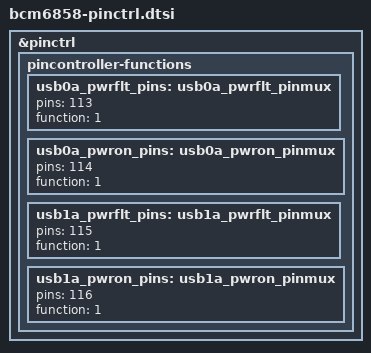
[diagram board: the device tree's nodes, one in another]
&pinctrl {
	pincontroller-functions {
		usb0a_pwrflt_pins: usb0a_pwrflt_pinmux {
			pins = <113>;
			function = <1>;
		};

		usb0a_pwron_pins: usb0a_pwron_pinmux {
			pins = <114>;
			function = <1>;
		};

		usb1a_pwrflt_pins: usb1a_pwrflt_pinmux {
			pins = <115>;
			function = <1>;
		};

		usb1a_pwron_pins: usb1a_pwron_pinmux {
			pins = <116>;
			function = <1>;
		};
	};
};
